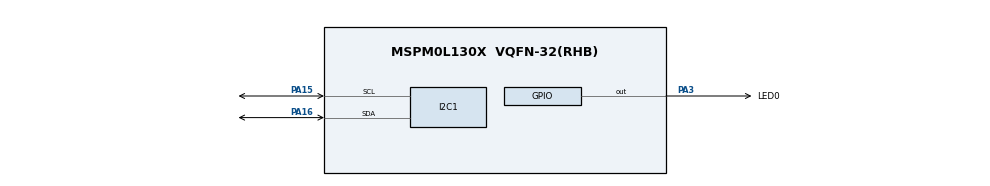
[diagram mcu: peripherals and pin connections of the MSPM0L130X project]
/**
 * @cliArgs --device "MSPM0L130X" --package "VQFN-32(RHB)" --part "Default" --product "mspm0_sdk@1.20.01.06"
 * @versions {"tool":"1.18.1+3343"}
 */

/**
 * Import the modules used in this configuration.
 */
const Board  = scripting.addModule("/ti/driverlib/Board");
const GPIO   = scripting.addModule("/ti/driverlib/GPIO", {}, false);
const GPIO1  = GPIO.addInstance();
const GPIO2  = GPIO.addInstance();
const GPIO3  = GPIO.addInstance();
const I2C    = scripting.addModule("/ti/driverlib/I2C", {}, false);
const I2C1   = I2C.addInstance();
const SYSCTL = scripting.addModule("/ti/driverlib/SYSCTL");
const TIMER  = scripting.addModule("/ti/driverlib/TIMER", {}, false);
const TIMER1 = TIMER.addInstance();
const UART   = scripting.addModule("/ti/driverlib/UART", {}, false);
const UART1  = UART.addInstance();

/**
 * Write custom configuration values to the imported modules.
 */

GPIO1.$name                          = "GPIO_GRP_0";
GPIO1.associatedPins.create(4);
GPIO1.associatedPins[0].$name        = "CS";
GPIO1.associatedPins[0].assignedPort = "PORTA";
GPIO1.associatedPins[0].initialValue = "SET";
GPIO1.associatedPins[0].ioStructure  = "SD";
GPIO1.associatedPins[0].assignedPin  = "2";
GPIO1.associatedPins[1].assignedPin  = "6";
GPIO1.associatedPins[1].$name        = "D0";
GPIO1.associatedPins[2].$name        = "D1";
GPIO1.associatedPins[2].assignedPin  = "5";
GPIO1.associatedPins[3].$name        = "DC";
GPIO1.associatedPins[3].assignedPin  = "4";

GPIO2.$name                          = "Light";
GPIO2.associatedPins.create(3);
GPIO2.associatedPins[0].assignedPort = "PORTA";
GPIO2.associatedPins[0].$name        = "LED1";
GPIO2.associatedPins[0].assignedPin  = "8";
GPIO2.associatedPins[0].initialValue = "SET";
GPIO2.associatedPins[1].$name        = "LED2";
GPIO2.associatedPins[1].assignedPin  = "9";
GPIO2.associatedPins[1].initialValue = "SET";
GPIO2.associatedPins[2].$name        = "LED0";
GPIO2.associatedPins[2].pin.$assign  = "PA3";

GPIO3.$name                               = "Matrix";
GPIO3.associatedPins.create(8);
GPIO3.associatedPins[0].assignedPort      = "PORTA";
GPIO3.associatedPins[0].assignedPin       = "0";
GPIO3.associatedPins[0].$name             = "H1";
GPIO3.associatedPins[0].internalResistor  = "PULL_UP";
GPIO3.associatedPins[1].assignedPin       = "1";
GPIO3.associatedPins[1].$name             = "H2";
GPIO3.associatedPins[1].internalResistor  = "PULL_UP";
GPIO3.associatedPins[2].assignedPin       = "7";
GPIO3.associatedPins[2].$name             = "H3";
GPIO3.associatedPins[2].internalResistor  = "PULL_UP";
GPIO3.associatedPins[3].assignedPin       = "12";
GPIO3.associatedPins[3].$name             = "H4";
GPIO3.associatedPins[3].internalResistor  = "PULL_UP";
GPIO3.associatedPins[4].$name             = "V1";
GPIO3.associatedPins[4].assignedPin       = "13";
GPIO3.associatedPins[4].internalResistor  = "PULL_UP";
GPIO3.associatedPins[4].direction         = "INPUT";
GPIO3.associatedPins[4].polarity          = "FALL";
GPIO3.associatedPins[5].$name             = "V2";
GPIO3.associatedPins[5].assignedPin       = "14";
GPIO3.associatedPins[5].internalResistor  = "PULL_UP";
GPIO3.associatedPins[5].direction         = "INPUT";
GPIO3.associatedPins[6].$name             = "V3";
GPIO3.associatedPins[6].assignedPin       = "17";
GPIO3.associatedPins[6].internalResistor  = "PULL_UP";
GPIO3.associatedPins[6].direction         = "INPUT";
GPIO3.associatedPins[7].$name             = "V4";
GPIO3.associatedPins[7].assignedPin       = "18";
GPIO3.associatedPins[7].internalResistor  = "PULL_UP";
GPIO3.associatedPins[7].direction         = "INPUT";
GPIO3.associatedPins[7].interruptEn       = true;
GPIO3.associatedPins[7].polarity          = "FALL";
GPIO3.associatedPins[7].interruptPriority = "1";

I2C1.$name                     = "I2C_0";
I2C1.basicEnableController     = true;
I2C1.advControllerRXFIFOTRIG   = "BYTES_8";
I2C1.advControllerTXFIFOTRIG   = "BYTES_7";
I2C1.peripheral.$assign        = "I2C1";
I2C1.peripheral.sdaPin.$assign = "PA16";
I2C1.peripheral.sclPin.$assign = "PA15";
I2C1.sdaPinConfig.$name        = "ti_driverlib_gpio_GPIOPinGeneric2";
I2C1.sclPinConfig.$name        = "ti_driverlib_gpio_GPIOPinGeneric3";

SYSCTL.MFCLKEn = true;

TIMER1.$name             = "clock_1s";
TIMER1.timerClkSrc       = "MFCLK";
TIMER1.timerClkPrescale  = 256;
TIMER1.timerMode         = "PERIODIC";
TIMER1.interrupts        = ["ZERO"];
TIMER1.timerPeriod       = "1s";
TIMER1.interruptPriority = "3";

UART1.$name              = "UART_0";
UART1.enabledInterrupts  = ["RX"];
UART1.uartClkSrc         = "MFCLK";
UART1.interruptPriority  = "0";
UART1.peripheral.$assign = "UART1";
UART1.txPinConfig.$name  = "ti_driverlib_gpio_GPIOPinGeneric0";
UART1.rxPinConfig.$name  = "ti_driverlib_gpio_GPIOPinGeneric1";

/**
 * Pinmux solution for unlocked pins/peripherals. This ensures that minor changes to the automatic solver in a future
 * version of the tool will not impact the pinmux you originally saw.  These lines can be completely deleted in order to
 * re-solve from scratch.
 */
Board.peripheral.$suggestSolution            = "DEBUGSS";
Board.peripheral.swclkPin.$suggestSolution   = "PA20";
Board.peripheral.swdioPin.$suggestSolution   = "PA19";
GPIO1.associatedPins[0].pin.$suggestSolution = "PA2";
GPIO1.associatedPins[1].pin.$suggestSolution = "PA6";
GPIO1.associatedPins[2].pin.$suggestSolution = "PA5";
GPIO1.associatedPins[3].pin.$suggestSolution = "PA4";
GPIO2.associatedPins[0].pin.$suggestSolution = "PA8";
GPIO2.associatedPins[1].pin.$suggestSolution = "PA9";
GPIO3.associatedPins[0].pin.$suggestSolution = "PA0";
GPIO3.associatedPins[1].pin.$suggestSolution = "PA1";
GPIO3.associatedPins[2].pin.$suggestSolution = "PA7";
GPIO3.associatedPins[3].pin.$suggestSolution = "PA12";
GPIO3.associatedPins[4].pin.$suggestSolution = "PA13";
GPIO3.associatedPins[5].pin.$suggestSolution = "PA14";
GPIO3.associatedPins[6].pin.$suggestSolution = "PA17/OPA1.IN0-";
GPIO3.associatedPins[7].pin.$suggestSolution = "PA18";
SYSCTL.peripheral.$suggestSolution           = "SYSCTL";
TIMER1.peripheral.$suggestSolution           = "TIMG0";
UART1.peripheral.rxPin.$suggestSolution      = "PA11";
UART1.peripheral.txPin.$suggestSolution      = "PA10";
